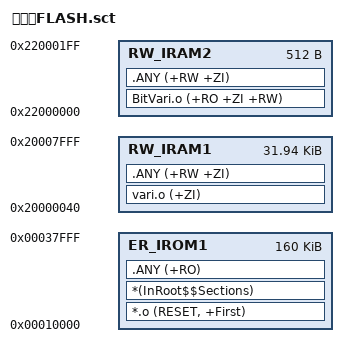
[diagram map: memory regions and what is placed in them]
; *************************************************************
; *** Scatter-Loading Description File generated by uVision ***
; *************************************************************
;                  总长  - 引导  - 配置
LR_IROM1 0x10000 (0x40000-0X10000-0x8000)  
{    ; load region size_region
  ER_IROM1 0x10000 (0x40000-0X10000-0x8000)
  {  ; load address = execution address
   *.o (RESET, +First)
   *(InRoot$$Sections)
   .ANY (+RO)
  }
  RW_IRAM1 0x20000040 (0x8000-0x40)
  {  ; RW data
    vari.o (+ZI)
   .ANY (+RW +ZI)
  }
  RW_IRAM2 0x22000000 0x00000200  
  {
    BitVari.o (+RO +ZI +RW)
   .ANY (+RW +ZI)
  }
}

